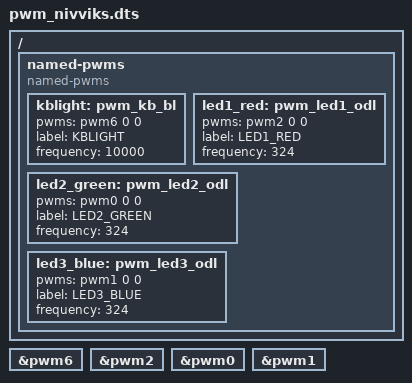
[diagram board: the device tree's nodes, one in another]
/* Copyright 2021 The Chromium OS Authors. All rights reserved.
 * Use of this source code is governed by a BSD-style license that can be
 * found in the LICENSE file.
 */

/ {
	named-pwms {
		compatible = "named-pwms";

		kblight: pwm_kb_bl {
			pwms = <&pwm6 0 0>;
			label = "KBLIGHT";
			frequency = <10000>;
		};

		led1_red: pwm_led1_odl {
			pwms = <&pwm2 0 0>;
			label = "LED1_RED";
			frequency = <324>;
		};
		led2_green: pwm_led2_odl {
			pwms = <&pwm0 0 0>;
			label = "LED2_GREEN";
			frequency = <324>;
		};
		led3_blue: pwm_led3_odl {
			pwms = <&pwm1 0 0>;
			label = "LED3_BLUE";
			frequency = <324>;
		};
	};
};

/* kblight */
&pwm6 {
	status = "okay";
};

/* LED1_RED */
&pwm2 {
	status = "okay";
};

/* LED2_GREEN */
&pwm0 {
	status = "okay";
};

/* LED3_BLUE */
&pwm1 {
	status = "okay";
};
